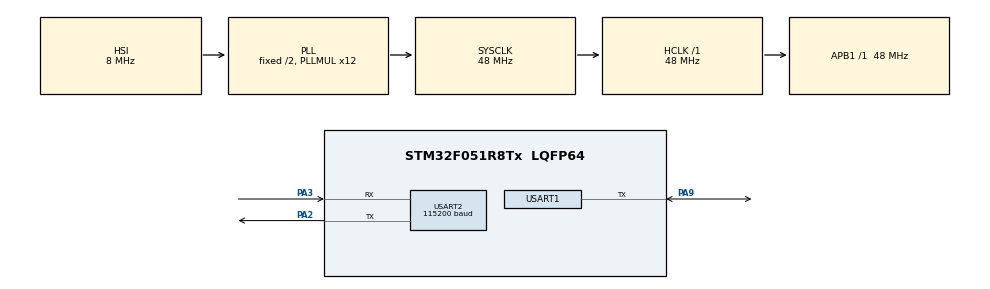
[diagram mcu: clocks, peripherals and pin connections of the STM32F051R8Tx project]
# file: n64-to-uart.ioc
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Mcu.Family=STM32F0
Mcu.Name=STM32F051R8Tx
Mcu.Package=LQFP64
PA2.Mode=Asynchronous
PA2.Signal=USART2_TX
PA3.Mode=Asynchronous
PA3.Signal=USART2_RX
PA9.Mode=Half_duplex(single_wire_mode)
PA9.Signal=USART1_TX
ProjectManager.HeapSize=0x200
ProjectManager.StackSize=0x400
ProjectManager.TargetToolchain=Makefile
RCC.AHBFreq_Value=48000000
RCC.APB1Freq_Value=48000000
RCC.APB1TimFreq_Value=48000000
RCC.HCLKFreq_Value=48000000
RCC.PLLMUL=RCC_PLL_MUL12
RCC.SYSCLKFreq_VALUE=48000000
RCC.SYSCLKSource=RCC_SYSCLKSOURCE_PLLCLK
USART1.BaudRate=3000000
USART1.StopBits=STOPBITS_2
USART1.VirtualMode-Half_duplex(single_wire_mode)=VM_ASYNC
USART1.WordLength=WORDLENGTH_9B
USART2.BaudRate=115200
USART2.VirtualMode-Asynchronous=VM_ASYNC
board=STM32F0DISCOVERY

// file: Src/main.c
/* USER CODE BEGIN Header */
/**
  ******************************************************************************
  * @file           : main.c
  * @brief          : Main program body
  ******************************************************************************
  * @attention
  *
  * Copyright (c) 2024 STMicroelectronics.
  * All rights reserved.
  *
  * This software is licensed under terms that can be found in the LICENSE file
  * in the root directory of this software component.
  * If no LICENSE file comes with this software, it is provided AS-IS.
  *
  ******************************************************************************
  */
/* USER CODE END Header */
#include "main.h"
//#include "newlib/sys/types.h"
#include "stm32f0xx_hal.h"
#include "stm32f0xx_hal_uart.h"
#include "usart.h"
#include "gpio.h"
#include <stdint.h>
#include <stdio.h>

/* USER CODE BEGIN Includes */
#include "stm32f0xx_ll_gpio.h"
/* USER CODE END Includes */

/* USER CODE BEGIN PV */
void read_n64_joystick(uint8_t* x_axis, uint8_t* y_axis);
/* USER CODE END PV */

void SystemClock_Config(void);

int main(void)
{

  /* MCU Configuration--------------------------------------------------------*/

  /* Reset of all peripherals, Initializes the Flash interface and the Systick. */
  HAL_Init();

  /* Configure the system clock */
  SystemClock_Config();

  /* Initialize all configured peripherals */
  MX_GPIO_Init();
  MX_USART1_UART_Init();
  MX_USART2_UART_Init();
  /* USER CODE BEGIN 2 */
<<<<<<< HEAD:code/n64-to-uart/Src/main.c
=======
  HAL_TIM_Base_Start_IT(&htim1);
  int16_t x_value;
  int16_t y_value;

  float x_standard_value = 0.00;
  float y_standard_value = 0.00;

  int16_t x_max_input = 0;
  int16_t x_min_input = 4095;
  int16_t y_max_input = 0;
  int16_t y_min_input = 4095;
  int16_t max_output = 1;
  int16_t min_output = -1;
>>>>>>> dreamcast:code/dreamcast-usart-cubeMX/Src/main.c

  /* USER CODE END 2 */

  /* Infinite loop */
  /* USER CODE BEGIN WHILE */
  while (1)
  {
<<<<<<< HEAD:code/n64-to-uart/Src/main.c
    uint8_t x = 0;
    uint8_t y = 0;
    read_n64_joystick(&x, &y);
    printf("X axis: %d, Y axis %d \r\n", 15, 124);
    HAL_Delay(1000);
=======

	x_value = read_adc_channel(0);
	y_value = read_adc_channel(1);

	if (x_value > x_max_input) {
		x_max_input = x_value;
	}
	if (x_value < x_min_input) {
		x_min_input = x_value;
	}
	if (y_value > y_max_input) {
		y_max_input = y_value;
	}
	if (y_value < y_min_input) {
		y_min_input = y_value;
	}

	x_standard_value = (((float) x_value - x_min_input) * (max_output - min_output))/(x_max_input - x_min_input) + min_output;
	y_standard_value = (((float) y_value - y_min_input) * (max_output - min_output))/(y_max_input - y_min_input) + min_output;

	printf("%d,%.2f,%.2f\r\n", get_time_ms(), x_standard_value, y_standard_value);

	delay_ms(10);
>>>>>>> dreamcast:code/dreamcast-usart-cubeMX/Src/main.c
    /* USER CODE END WHILE */

  }
}

void SystemClock_Config(void)
{
  RCC_OscInitTypeDef RCC_OscInitStruct = {0};
  RCC_ClkInitTypeDef RCC_ClkInitStruct = {0};
  RCC_PeriphCLKInitTypeDef PeriphClkInit = {0};

  /** Initializes the RCC Oscillators according to the specified parameters
  * in the RCC_OscInitTypeDef structure.
  */
  RCC_OscInitStruct.OscillatorType = RCC_OSCILLATORTYPE_HSI;
  RCC_OscInitStruct.HSIState = RCC_HSI_ON;
  RCC_OscInitStruct.HSICalibrationValue = RCC_HSICALIBRATION_DEFAULT;
  RCC_OscInitStruct.PLL.PLLState = RCC_PLL_ON;
  RCC_OscInitStruct.PLL.PLLSource = RCC_PLLSOURCE_HSI;
  RCC_OscInitStruct.PLL.PLLMUL = RCC_PLL_MUL12;
  RCC_OscInitStruct.PLL.PREDIV = RCC_PREDIV_DIV1;
  if (HAL_RCC_OscConfig(&RCC_OscInitStruct) != HAL_OK)
  {
    Error_Handler();
  }

  /** Initializes the CPU, AHB and APB buses clocks
  */
  RCC_ClkInitStruct.ClockType = RCC_CLOCKTYPE_HCLK|RCC_CLOCKTYPE_SYSCLK
                              |RCC_CLOCKTYPE_PCLK1;
  RCC_ClkInitStruct.SYSCLKSource = RCC_SYSCLKSOURCE_PLLCLK;
  RCC_ClkInitStruct.AHBCLKDivider = RCC_SYSCLK_DIV1;
  RCC_ClkInitStruct.APB1CLKDivider = RCC_HCLK_DIV1;

  if (HAL_RCC_ClockConfig(&RCC_ClkInitStruct, FLASH_LATENCY_1) != HAL_OK)
  {
    Error_Handler();
  }
  PeriphClkInit.PeriphClockSelection = RCC_PERIPHCLK_USART1;
  PeriphClkInit.Usart1ClockSelection = RCC_USART1CLKSOURCE_PCLK1;
  if (HAL_RCCEx_PeriphCLKConfig(&PeriphClkInit) != HAL_OK)
  {
    Error_Handler();
  }
}

/* USER CODE BEGIN 4 */

/**
 *
 * @brief This function initiates contact with n64 controller, then collects data.
 * @retval None, collected data is mapped to provided addresses.
 */
void read_n64_joystick(uint8_t* x_axis, uint8_t* y_axis)
{
  const uint16_t get_button_byte[] = {0x0100, 0x0100, 0x0100, 0x0100, 0x0100, 0x0100, 0x0100, 0x01fc, 0x01e0, 0x0100};
  uint8_t receiveive_buffer[60] = {0};
  HAL_HalfDuplex_EnableTransmitter(&huart1);
  HAL_UART_Transmit(&huart1, (uint8_t*)get_button_byte, 9, 1000);
  huart1.Instance->RDR = (uint16_t)(0x01e0 & 0x01FFU);
  while (!LL_GPIO_IsInputPinSet(GPIOA, LL_GPIO_PIN_9));
  HAL_HalfDuplex_EnableReceiver(&huart1);
  HAL_UART_Receive(&huart1, receiveive_buffer, 60, 10);
  uint8_t x_axis_temp = 0;
  for (int i = 0; i < 60; i++)
  {
    printf("Recieve Buffer %d, is: %d.  ", i, receiveive_buffer[i]);
    if (!(i%3))
    {
      printf("\r\n");
    }
  }
  for(int i = 0; i < 8; i++)
  {
    uint8_t temp = ((receiveive_buffer[42-(i*2)] & 0x10) >> 4);
    x_axis_temp = x_axis_temp | (temp << i);
  }
  uint8_t y_axis_temp = 0;
  for(int i = 0; i < 8; i++)
  {
    uint8_t temp = ((receiveive_buffer[58-(i*2)] & 0x10) >> 4);
    y_axis_temp = y_axis_temp | (temp << i);
  }
  printf("X axis: %d, Y axis %d \r\n", x_axis_temp, y_axis_temp);
  *x_axis = x_axis_temp;
  *y_axis = y_axis_temp;
  return;
}

/* USER CODE END 4 */

void Error_Handler(void)
{
  __disable_irq();
  while (1)
  {
  }
}
